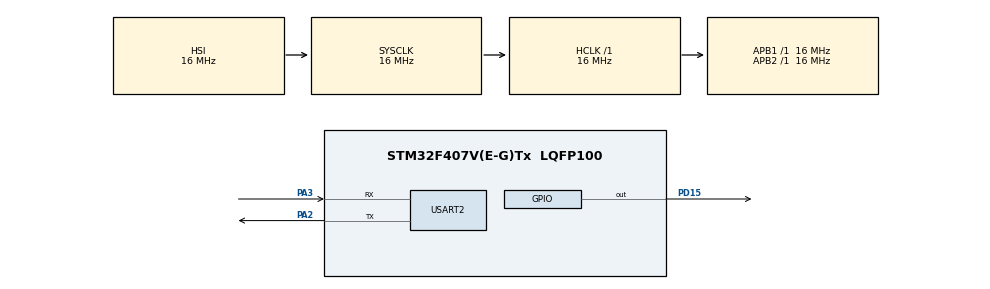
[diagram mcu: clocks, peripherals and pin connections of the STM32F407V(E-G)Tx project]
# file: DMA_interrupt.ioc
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Mcu.Family=STM32F4
RCC.CortexFreq_Value=16000000
Dma.USART2_TX.0.MemInc=DMA_MINC_ENABLE
Dma.USART2_TX.0.PeriphDataAlignment=DMA_PDATAALIGN_BYTE
Dma.USART2_TX.0.FIFOMode=DMA_FIFOMODE_DISABLE
ProjectManager.StackSize=0x400
PA3.Mode=Asynchronous
Dma.USART2_TX.0.Priority=DMA_PRIORITY_LOW
ProjectManager.TargetToolchain=STM32CubeIDE
RCC.LSE_VALUE=32768
RCC.AHBFreq_Value=16000000
RCC.HSE_VALUE=25000000
board=custom
RCC.VCOOutputFreq_Value=192000000
RCC.APB2Freq_Value=16000000
Dma.USART2_TX.0.MemDataAlignment=DMA_MDATAALIGN_BYTE
Dma.USART2_TX.0.Direction=DMA_MEMORY_TO_PERIPH
Mcu.Name=STM32F407V(E-G)Tx
Dma.USART2_TX.0.Instance=DMA1_Stream6
PA2.Signal=USART2_TX
RCC.SYSCLKFreq_VALUE=16000000
Mcu.Package=LQFP100
Dma.USART2_TX.0.PeriphInc=DMA_PINC_DISABLE
USART2.VirtualMode=VM_ASYNC
ProjectManager.HeapSize=0x200
RCC.HSI_VALUE=16000000
Dma.USART2_TX.0.Mode=DMA_NORMAL
NVIC.PriorityGroup=NVIC_PRIORITYGROUP_4
PA2.Mode=Asynchronous
RCC.APB1Freq_Value=16000000
NVIC.DMA1_Stream6_IRQn=true\:0\:0\:false\:false\:true\:false\:true
Dma.Request0=USART2_TX
PD15.Signal=GPIO_Output
PA3.Signal=USART2_RX

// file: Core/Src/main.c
/* USER CODE BEGIN Header */
/**
  ******************************************************************************
  * @file           : main.c
  * @brief          : Main program body
  ******************************************************************************
  * @attention
  *
  * <h2><center>&copy; Copyright (c) 2021 STMicroelectronics.
  * All rights reserved.</center></h2>
  *
  * This software component is licensed by ST under BSD 3-Clause license,
  * the "License"; You may not use this file except in compliance with the
  * License. You may obtain a copy of the License at:
  *                        opensource.org/licenses/BSD-3-Clause
  *
  ******************************************************************************
  */
/* USER CODE END Header */
#include "main.h"

/* USER CODE BEGIN Includes */
#include "string.h"
/* USER CODE END Includes */

UART_HandleTypeDef huart2;
DMA_HandleTypeDef hdma_usart2_tx;

/* USER CODE BEGIN PV */
char *msg = "\r\nCiao amanti dell'STM32! Questo messaggio viene inviato in DMA Mode...\r\n";
/* USER CODE END PV */

void SystemClock_Config(void);
static void MX_GPIO_Init(void);
static void MX_DMA_Init(void);
static void MX_USART2_UART_Init(void);
void DMATransferComplete(DMA_HandleTypeDef *hdma);

int main(void)
{

  /* MCU Configuration--------------------------------------------------------*/

  /* Reset of all peripherals, Initializes the Flash interface and the Systick. */
  HAL_Init();

  /* Configure the system clock */
  SystemClock_Config();

  /* Initialize all configured peripherals */
  MX_GPIO_Init();
  MX_DMA_Init();
  MX_USART2_UART_Init();
  /* USER CODE BEGIN 2 */
  HAL_DMA_Start_IT(&hdma_usart2_tx,  (uint32_t)msg,  (uint32_t)&huart2.Instance->DR, strlen(msg));
  //Enable UART in DMA mode
  huart2.Instance->CR3 |= USART_CR3_DMAT;
  /* USER CODE END 2 */

  /* Infinite loop */
  while (1)
  {

  }
}

void DMATransferComplete(DMA_HandleTypeDef *hdma) {
  if(hdma->Instance == DMA1_Stream6 && hdma->Init.Channel == DMA_CHANNEL_4) {
    //Disable UART DMA mode
    huart2.Instance->CR3 &= ~USART_CR3_DMAT;
    //Turn LD2 ON
    HAL_GPIO_WritePin(GPIOD, GPIO_PIN_15, GPIO_PIN_SET);
  }
}

void SystemClock_Config(void)
{
  RCC_OscInitTypeDef RCC_OscInitStruct = {0};
  RCC_ClkInitTypeDef RCC_ClkInitStruct = {0};

  /** Configure the main internal regulator output voltage
  */
  __HAL_RCC_PWR_CLK_ENABLE();
  __HAL_PWR_VOLTAGESCALING_CONFIG(PWR_REGULATOR_VOLTAGE_SCALE1);
  /** Initializes the RCC Oscillators according to the specified parameters
  * in the RCC_OscInitTypeDef structure.
  */
  RCC_OscInitStruct.OscillatorType = RCC_OSCILLATORTYPE_HSI;
  RCC_OscInitStruct.HSIState = RCC_HSI_ON;
  RCC_OscInitStruct.HSICalibrationValue = RCC_HSICALIBRATION_DEFAULT;
  RCC_OscInitStruct.PLL.PLLState = RCC_PLL_NONE;
  if (HAL_RCC_OscConfig(&RCC_OscInitStruct) != HAL_OK)
  {
    Error_Handler();
  }
  /** Initializes the CPU, AHB and APB buses clocks
  */
  RCC_ClkInitStruct.ClockType = RCC_CLOCKTYPE_HCLK|RCC_CLOCKTYPE_SYSCLK
                              |RCC_CLOCKTYPE_PCLK1|RCC_CLOCKTYPE_PCLK2;
  RCC_ClkInitStruct.SYSCLKSource = RCC_SYSCLKSOURCE_HSI;
  RCC_ClkInitStruct.AHBCLKDivider = RCC_SYSCLK_DIV1;
  RCC_ClkInitStruct.APB1CLKDivider = RCC_HCLK_DIV1;
  RCC_ClkInitStruct.APB2CLKDivider = RCC_HCLK_DIV1;

  if (HAL_RCC_ClockConfig(&RCC_ClkInitStruct, FLASH_LATENCY_0) != HAL_OK)
  {
    Error_Handler();
  }
}

static void MX_USART2_UART_Init(void)
{

  huart2.Instance = USART2;
  huart2.Init.BaudRate = 115200;
  huart2.Init.WordLength = UART_WORDLENGTH_8B;
  huart2.Init.StopBits = UART_STOPBITS_1;
  huart2.Init.Parity = UART_PARITY_NONE;
  huart2.Init.Mode = UART_MODE_TX_RX;
  huart2.Init.HwFlowCtl = UART_HWCONTROL_NONE;
  huart2.Init.OverSampling = UART_OVERSAMPLING_16;
  if (HAL_UART_Init(&huart2) != HAL_OK)
  {
    Error_Handler();
  }

}

static void MX_DMA_Init(void)
{

  /* DMA controller clock enable */
  __HAL_RCC_DMA1_CLK_ENABLE();

  /* DMA interrupt init */
  /* DMA1_Stream6_IRQn interrupt configuration */
  HAL_NVIC_SetPriority(DMA1_Stream6_IRQn, 0, 0);
  HAL_NVIC_EnableIRQ(DMA1_Stream6_IRQn);

}

static void MX_GPIO_Init(void)
{
  GPIO_InitTypeDef GPIO_InitStruct = {0};

  /* GPIO Ports Clock Enable */
  __HAL_RCC_GPIOA_CLK_ENABLE();
  __HAL_RCC_GPIOD_CLK_ENABLE();

  /*Configure GPIO pin Output Level */
  HAL_GPIO_WritePin(GPIOD, GPIO_PIN_15, GPIO_PIN_RESET);

  /*Configure GPIO pin : PD15 */
  GPIO_InitStruct.Pin = GPIO_PIN_15;
  GPIO_InitStruct.Mode = GPIO_MODE_OUTPUT_PP;
  GPIO_InitStruct.Pull = GPIO_NOPULL;
  GPIO_InitStruct.Speed = GPIO_SPEED_FREQ_LOW;
  HAL_GPIO_Init(GPIOD, &GPIO_InitStruct);

}

void Error_Handler(void)
{
  __disable_irq();
  while (1)
  {
  }
}

/************************ (C) COPYRIGHT STMicroelectronics *****END OF FILE****/
